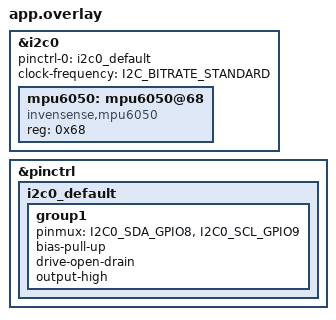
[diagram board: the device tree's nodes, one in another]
/* Sama persis dengan overlay Tahap 1, lihat catatan di sana soal wiring dan alamat I2C. */
#include <zephyr/dt-bindings/i2c/i2c.h>

&i2c0 {
	status = "okay";
	pinctrl-0 = <&i2c0_default>;
	pinctrl-names = "default";
	clock-frequency = <I2C_BITRATE_STANDARD>;

	mpu6050: mpu6050@68 {
		compatible = "invensense,mpu6050";
		reg = <0x68>;
		status = "okay";
	};
};

&pinctrl {
	i2c0_default: i2c0_default {
		group1 {
			pinmux = <I2C0_SDA_GPIO8>, <I2C0_SCL_GPIO9>;
			bias-pull-up;
			drive-open-drain;
			output-high;
		};
	};
};
